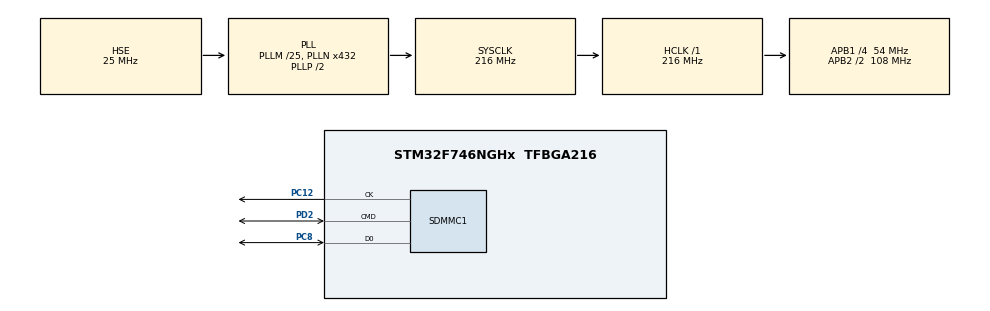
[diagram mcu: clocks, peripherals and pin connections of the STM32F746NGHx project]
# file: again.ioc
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CORTEX_M7.ART_ACCLERATOR_ENABLE=1
CORTEX_M7.CPU_DCache=Enabled
CORTEX_M7.CPU_ICache=Enabled
CORTEX_M7.PREFETCH_ENABLE=1
FATFS._USE_LFN=2
Mcu.Family=STM32F7
Mcu.Name=STM32F746NGHx
Mcu.Package=TFBGA216
NVIC.PriorityGroup=NVIC_PRIORITYGROUP_4
NVIC.RCC_IRQn=true\:0\:0\:false\:false\:true\:true
PA13.Mode=Serial_Wire
PA13.Signal=SYS_JTMS-SWDIO
PA14.Mode=Serial_Wire
PA14.Signal=SYS_JTCK-SWCLK
PC12.Mode=SD_1_bit
PC12.Signal=SDMMC1_CK
PC8.Mode=SD_1_bit
PC8.Signal=SDMMC1_D0
PD2.Mode=SD_1_bit
PD2.Signal=SDMMC1_CMD
PH0/OSC_IN.Mode=HSE-External-Oscillator
PH0/OSC_IN.Signal=RCC_OSC_IN
PH1/OSC_OUT.Mode=HSE-External-Oscillator
PH1/OSC_OUT.Signal=RCC_OSC_OUT
ProjectManager.HeapSize=0x200
ProjectManager.StackSize=0x1000
ProjectManager.TargetToolchain=MDK-ARM V5
RCC.AHBFreq_Value=216000000
RCC.APB1CLKDivider=RCC_HCLK_DIV4
RCC.APB1Freq_Value=54000000
RCC.APB1TimFreq_Value=108000000
RCC.APB2CLKDivider=RCC_HCLK_DIV2
RCC.APB2Freq_Value=108000000
RCC.APB2TimFreq_Value=216000000
RCC.CortexFreq_Value=216000000
RCC.HCLKFreq_Value=216000000
RCC.HSE_VALUE=25000000
RCC.HSI_VALUE=16000000
RCC.LSE_VALUE=32768
RCC.PLLI2SN=100
RCC.PLLM=25
RCC.PLLN=432
RCC.PLLQ=9
RCC.PLLSAIN=384
RCC.PLLSAIP=RCC_PLLSAIP_DIV8
RCC.PLLSAIR=5
RCC.PLLSAIRDiv=RCC_PLLSAIDIVR_8
RCC.PLLSourceVirtual=RCC_PLLSOURCE_HSE
RCC.SDMMCClockSelection=RCC_SDMMC1CLKSOURCE_CLK48
RCC.SYSCLKFreq_VALUE=216000000
RCC.SYSCLKSource=RCC_SYSCLKSOURCE_PLLCLK
RCC.USBFreq_Value=48000000
RCC.VCOOutputFreq_Value=432000000
VP_FATFS_VS_SDIO.Mode=SDIO
board=32F746GDISCOVERY

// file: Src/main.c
/**
  ******************************************************************************
  * @file           : main.c
  * @brief          : Main program body
  ******************************************************************************
  * This notice applies to any and all portions of this file
  * that are not between comment pairs USER CODE BEGIN and
  * USER CODE END. Other portions of this file, whether
  * inserted by the user or by software development tools
  * are owned by their respective copyright owners.
  *
  * Copyright (c) 2018 STMicroelectronics International N.V.
  * All rights reserved.
  *
  * Redistribution and use in source and binary forms, with or without
  * modification, are permitted, provided that the following conditions are met:
  *
  * 1. Redistribution of source code must retain the above copyright notice,
  *    this list of conditions and the following disclaimer.
  * 2. Redistributions in binary form must reproduce the above copyright notice,
  *    this list of conditions and the following disclaimer in the documentation
  *    and/or other materials provided with the distribution.
  * 3. Neither the name of STMicroelectronics nor the names of other
  *    contributors to this software may be used to endorse or promote products
  *    derived from this software without specific written permission.
  * 4. This software, including modifications and/or derivative works of this
  *    software, must execute solely and exclusively on microcontroller or
  *    microprocessor devices manufactured by or for STMicroelectronics.
  * 5. Redistribution and use of this software other than as permitted under
  *    this license is void and will automatically terminate your rights under
  *    this license.
  *
  * THIS SOFTWARE IS PROVIDED BY STMICROELECTRONICS AND CONTRIBUTORS "AS IS"
  * AND ANY EXPRESS, IMPLIED OR STATUTORY WARRANTIES, INCLUDING, BUT NOT
  * LIMITED TO, THE IMPLIED WARRANTIES OF MERCHANTABILITY, FITNESS FOR A
  * PARTICULAR PURPOSE AND NON-INFRINGEMENT OF THIRD PARTY INTELLECTUAL PROPERTY
  * RIGHTS ARE DISCLAIMED TO THE FULLEST EXTENT PERMITTED BY LAW. IN NO EVENT
  * SHALL STMICROELECTRONICS OR CONTRIBUTORS BE LIABLE FOR ANY DIRECT, INDIRECT,
  * INCIDENTAL, SPECIAL, EXEMPLARY, OR CONSEQUENTIAL DAMAGES (INCLUDING, BUT NOT
  * LIMITED TO, PROCUREMENT OF SUBSTITUTE GOODS OR SERVICES; LOSS OF USE, DATA,
  * OR PROFITS; OR BUSINESS INTERRUPTION) HOWEVER CAUSED AND ON ANY THEORY OF
  * LIABILITY, WHETHER IN CONTRACT, STRICT LIABILITY, OR TORT (INCLUDING
  * NEGLIGENCE OR OTHERWISE) ARISING IN ANY WAY OUT OF THE USE OF THIS SOFTWARE,
  * EVEN IF ADVISED OF THE POSSIBILITY OF SUCH DAMAGE.
  *
  ******************************************************************************
  */
#include "main.h"
#include "stm32f7xx_hal.h"
#include "fatfs.h"

SD_HandleTypeDef hsd1;

/* USER CODE BEGIN PV */
FRESULT result;
uint8_t res;
FATFS sdfat;
FIL myfile;
char buffer_write[50] = "This is SD card programming\r\n";
char buffer_read[50];
char SDpath[20];
uint32_t bytes_read,bytes_written;

enum _bool
	{
	false=0,
		true=1
  };
	typedef enum _bool boolean;
/* Private variables ---------------------------------------------------------*/

/* USER CODE END PV */

void SystemClock_Config(void);
static void MX_GPIO_Init(void);
static void MX_SDMMC1_SD_Init(void);

/* USER CODE BEGIN PFP */
	static void Handle_Error(void);
/* Private function prototypes -----------------------------------------------*/

/* USER CODE END PFP */

int main(void)
{

  /* Enable I-Cache-------------------------------------------------------------*/
  SCB_EnableICache();

  /* Enable D-Cache-------------------------------------------------------------*/
  SCB_EnableDCache();

  /* MCU Configuration----------------------------------------------------------*/

  /* Reset of all peripherals, Initializes the Flash interface and the Systick. */
  HAL_Init();

  /* Configure the system clock */
  SystemClock_Config();

  /* Initialize all configured peripherals */
  MX_GPIO_Init();
  MX_SDMMC1_SD_Init();
  MX_FATFS_Init();
  /* USER CODE BEGIN 2 */
	res = BSP_SD_Init();
	if(res!= MSD_OK)
	{
		Handle_Error();
	}

	result = f_mount(&sdfat,"",1);
	if(result!= FR_OK)
	{
		Handle_Error();
	}

	result = f_open(&myfile,"test.txt",FA_OPEN_ALWAYS|FA_WRITE|FA_READ);
	if(result!= FR_OK)
	{
		Handle_Error();
	}

	result = f_lseek(&myfile,f_size(&myfile));
	if(result!= FR_OK)
	{
		Handle_Error();
	}

	f_printf(&myfile,"%s",buffer_write);
	f_close(&myfile);

	result = f_open(&myfile,"test.txt",FA_READ);
	if(result!= FR_OK)
	{
		Handle_Error();
	}

	result = f_read(&myfile,buffer_read,50,&bytes_read);
	if(result!= FR_OK)
	{
		Handle_Error();
	}

	result = f_close(&myfile);
	if(result!= FR_OK)
	{
		Handle_Error();
	}
	else
		HAL_GPIO_WritePin(GPIOI,GPIO_PIN_1,GPIO_PIN_SET);

	f_mount(0,"",1);

  /* USER CODE END 2 */

  /* Infinite loop */
  while (1)
  {

  }

}

void SystemClock_Config(void)
{

  RCC_OscInitTypeDef RCC_OscInitStruct;
  RCC_ClkInitTypeDef RCC_ClkInitStruct;
  RCC_PeriphCLKInitTypeDef PeriphClkInitStruct;

    /**Configure the main internal regulator output voltage
    */
  __HAL_RCC_PWR_CLK_ENABLE();

  __HAL_PWR_VOLTAGESCALING_CONFIG(PWR_REGULATOR_VOLTAGE_SCALE1);

    /**Initializes the CPU, AHB and APB busses clocks
    */
  RCC_OscInitStruct.OscillatorType = RCC_OSCILLATORTYPE_HSE;
  RCC_OscInitStruct.HSEState = RCC_HSE_ON;
  RCC_OscInitStruct.PLL.PLLState = RCC_PLL_ON;
  RCC_OscInitStruct.PLL.PLLSource = RCC_PLLSOURCE_HSE;
  RCC_OscInitStruct.PLL.PLLM = 25;
  RCC_OscInitStruct.PLL.PLLN = 432;
  RCC_OscInitStruct.PLL.PLLP = RCC_PLLP_DIV2;
  RCC_OscInitStruct.PLL.PLLQ = 9;
  if (HAL_RCC_OscConfig(&RCC_OscInitStruct) != HAL_OK)
  {
    _Error_Handler(__FILE__, __LINE__);
  }

    /**Activate the Over-Drive mode
    */
  if (HAL_PWREx_EnableOverDrive() != HAL_OK)
  {
    _Error_Handler(__FILE__, __LINE__);
  }

    /**Initializes the CPU, AHB and APB busses clocks
    */
  RCC_ClkInitStruct.ClockType = RCC_CLOCKTYPE_HCLK|RCC_CLOCKTYPE_SYSCLK
                              |RCC_CLOCKTYPE_PCLK1|RCC_CLOCKTYPE_PCLK2;
  RCC_ClkInitStruct.SYSCLKSource = RCC_SYSCLKSOURCE_PLLCLK;
  RCC_ClkInitStruct.AHBCLKDivider = RCC_SYSCLK_DIV1;
  RCC_ClkInitStruct.APB1CLKDivider = RCC_HCLK_DIV4;
  RCC_ClkInitStruct.APB2CLKDivider = RCC_HCLK_DIV2;

  if (HAL_RCC_ClockConfig(&RCC_ClkInitStruct, FLASH_LATENCY_7) != HAL_OK)
  {
    _Error_Handler(__FILE__, __LINE__);
  }

  PeriphClkInitStruct.PeriphClockSelection = RCC_PERIPHCLK_SDMMC1|RCC_PERIPHCLK_CLK48;
  PeriphClkInitStruct.Clk48ClockSelection = RCC_CLK48SOURCE_PLL;
  PeriphClkInitStruct.Sdmmc1ClockSelection = RCC_SDMMC1CLKSOURCE_CLK48;
  if (HAL_RCCEx_PeriphCLKConfig(&PeriphClkInitStruct) != HAL_OK)
  {
    _Error_Handler(__FILE__, __LINE__);
  }

    /**Configure the Systick interrupt time
    */
  HAL_SYSTICK_Config(HAL_RCC_GetHCLKFreq()/1000);

    /**Configure the Systick
    */
  HAL_SYSTICK_CLKSourceConfig(SYSTICK_CLKSOURCE_HCLK);

  /* SysTick_IRQn interrupt configuration */
  HAL_NVIC_SetPriority(SysTick_IRQn, 0, 0);
}

/* SDMMC1 init function */
static void MX_SDMMC1_SD_Init(void)
{

  hsd1.Instance = SDMMC1;
  hsd1.Init.ClockEdge = SDMMC_CLOCK_EDGE_RISING;
  hsd1.Init.ClockBypass = SDMMC_CLOCK_BYPASS_ENABLE;			//I have changed here!, To be able to use a frequency higher than 24MHz, you should use the SDMMC peripheral in bypass mode
  hsd1.Init.ClockPowerSave = SDMMC_CLOCK_POWER_SAVE_DISABLE;
  hsd1.Init.BusWide = SDMMC_BUS_WIDE_1B;
  hsd1.Init.HardwareFlowControl = SDMMC_HARDWARE_FLOW_CONTROL_DISABLE;
  hsd1.Init.ClockDiv = 0;
	HAL_SD_Init(&hsd1);

}

/** Configure pins as
        * Analog
        * Input
        * Output
        * EVENT_OUT
        * EXTI
*/
static void MX_GPIO_Init(void)
{
		GPIO_InitTypeDef my_Pin1;

  /* GPIO Ports Clock Enable */
  __HAL_RCC_GPIOC_CLK_ENABLE();
  __HAL_RCC_GPIOA_CLK_ENABLE();
  __HAL_RCC_GPIOD_CLK_ENABLE();
  __HAL_RCC_GPIOH_CLK_ENABLE();
	__HAL_RCC_GPIOI_CLK_ENABLE();

		/******Configure GPIO pin : PI1 i.e User LED************/
	 my_Pin1.Pin = GPIO_PIN_1;
  my_Pin1.Mode = GPIO_MODE_OUTPUT_PP;
  my_Pin1.Pull = GPIO_NOPULL;
  my_Pin1.Speed = GPIO_SPEED_FREQ_LOW;
  HAL_GPIO_Init(GPIOI, &my_Pin1);

}

/* USER CODE BEGIN 4 */

void Handle_Error(void)																		//Added Function
{
	for(int i=0;i<10;i++)
	{
	HAL_GPIO_TogglePin(GPIOI,GPIO_PIN_1);
	HAL_Delay(100);
	}
	HAL_GPIO_WritePin(GPIOI,GPIO_PIN_1,GPIO_PIN_RESET);
}

/* USER CODE END 4 */

void _Error_Handler(char *file, int line)
{
  while(1)
  {
  }
}

/************************ (C) COPYRIGHT STMicroelectronics *****END OF FILE****/
